CM_ "AUTOGENERATED FILE, DO NOT EDIT";

CM_ "Imported file _nissan_common.dbc starts here";
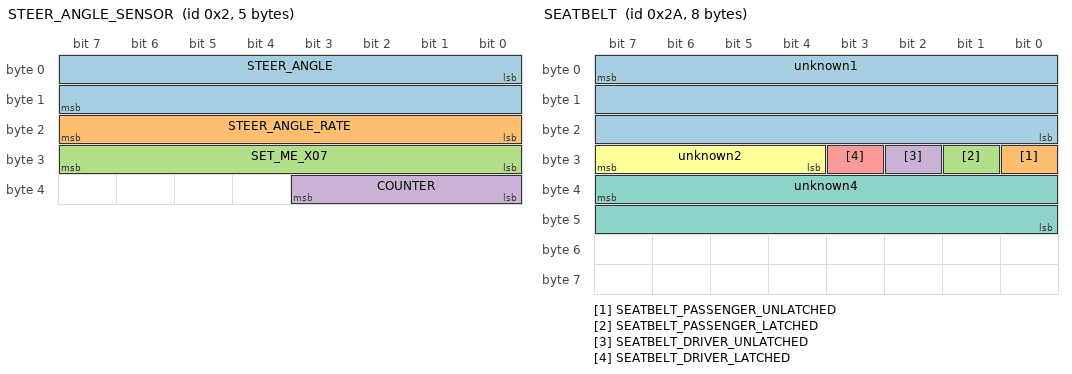
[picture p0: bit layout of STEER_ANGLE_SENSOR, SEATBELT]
BO_ 2 STEER_ANGLE_SENSOR: 5 XXX
 SG_ STEER_ANGLE : 0|16@1- (-0.1,0) [0|65535] "" XXX
 SG_ STEER_ANGLE_RATE : 16|8@1+ (1,0) [0|255] "" XXX
 SG_ SET_ME_X07 : 24|8@1+ (1,0) [0|255] "" XXX
 SG_ COUNTER : 32|4@1+ (1,0) [0|15] "" XXX

BO_ 42 SEATBELT: 8 XXX
 SG_ unknown1 : 7|24@0+ (1,0) [0|16777215] "" XXX
 SG_ SEATBELT_PASSENGER_UNLATCHED : 24|1@0+ (1,0) [0|1] "" XXX
 SG_ SEATBELT_PASSENGER_LATCHED : 25|1@0+ (1,0) [0|1] "" XXX
 SG_ SEATBELT_DRIVER_UNLATCHED : 26|1@0+ (1,0) [0|1] "" XXX
 SG_ SEATBELT_DRIVER_LATCHED : 27|1@1+ (1,0) [0|3] "" XXX
 SG_ unknown2 : 31|4@0+ (1,0) [0|15] "" XXX
 SG_ unknown4 : 39|16@0+ (1,0) [0|65535] "" XXX

BO_ 264 NEW_MSG_108: 3 XXX

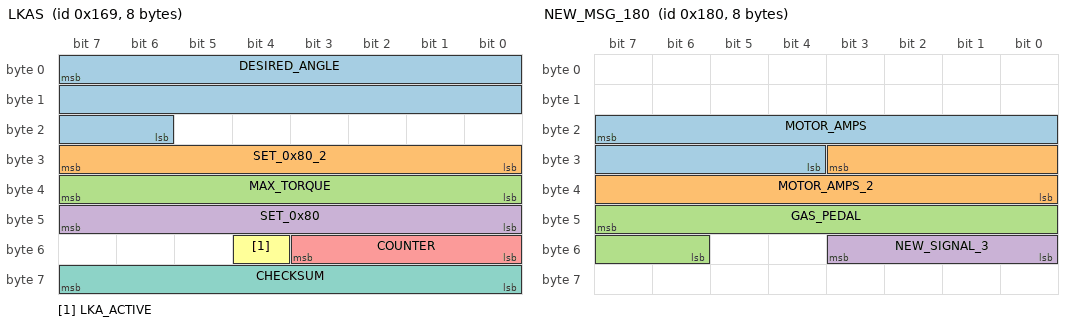
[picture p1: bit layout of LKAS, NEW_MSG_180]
BO_ 361 LKAS: 8 XXX
 SG_ DESIRED_ANGLE : 7|18@0+ (-0.01,1310) [-1311.43|1310] "" XXX
 SG_ SET_0x80_2 : 31|8@0+ (1,0) [0|255] "" XXX
 SG_ MAX_TORQUE : 39|8@0+ (0.01,0) [0|255] "Nm" XXX
 SG_ SET_0x80 : 47|8@0+ (1,0) [0|255] "" XXX
 SG_ COUNTER : 51|4@0+ (1,0) [0|15] "" XXX
 SG_ LKA_ACTIVE : 52|1@0+ (1,0) [0|15] "" XXX
 SG_ CHECKSUM : 63|8@0+ (1,0) [0|255] "" XXX

BO_ 372 NEW_MSG_174: 8 XXX
 SG_ GEARBOX_STATUS : 24|8@1+ (1,0) [0|255] "" XXX
 SG_ COUNTER : 32|4@1+ (1,0) [0|15] "" XXX

BO_ 384 NEW_MSG_180: 8 XXX
 SG_ MOTOR_AMPS : 23|12@0- (1,0) [0|4095] "" XXX
 SG_ MOTOR_AMPS_2 : 27|12@0- (1,0) [0|4095] "" XXX
 SG_ GAS_PEDAL : 47|10@0+ (1,0) [0|1023] "" XXX
 SG_ NEW_SIGNAL_3 : 51|4@0+ (1,0) [0|15] "" XXX

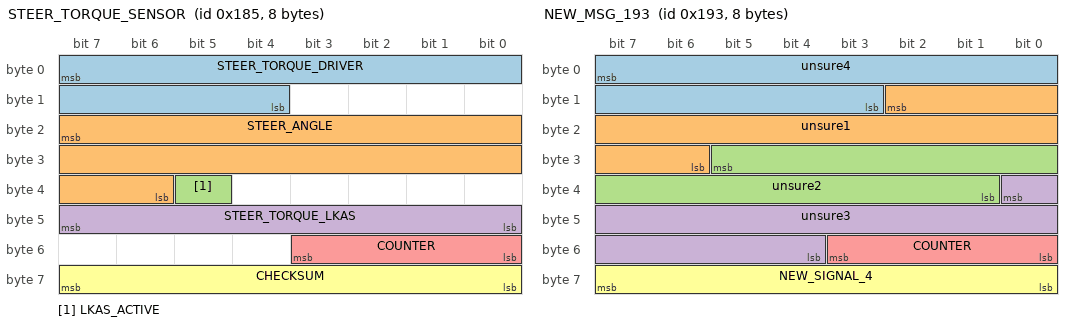
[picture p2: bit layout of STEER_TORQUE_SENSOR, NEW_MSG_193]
BO_ 389 STEER_TORQUE_SENSOR: 8 XXX
 SG_ STEER_TORQUE_DRIVER : 7|12@0+ (-0.01,20.47) [0|4095] "Nm" XXX
 SG_ STEER_ANGLE : 23|18@0+ (-0.01,1310) [0|262143] "" XXX
 SG_ LKAS_ACTIVE : 37|1@0+ (1,0) [0|3] "" XXX
 SG_ STEER_TORQUE_LKAS : 47|8@0+ (1,0) [0|255] "" XXX
 SG_ COUNTER : 51|4@0+ (1,0) [0|15] "" XXX
 SG_ CHECKSUM : 63|8@0+ (1,0) [0|127] "" XXX

BO_ 403 NEW_MSG_193: 8 XXX
 SG_ unsure4 : 7|13@0+ (0.1,-400) [0|8191] "" XXX
 SG_ unsure1 : 10|13@0+ (0.1,-400) [0|8191] "" XXX
 SG_ unsure2 : 29|13@0+ (0.1,-400) [0|8191] "" XXX
 SG_ unsure3 : 32|13@0+ (0.1,-400) [0|8191] "" XXX
 SG_ COUNTER : 51|4@0+ (1,0) [0|15] "" XXX
 SG_ NEW_SIGNAL_4 : 63|8@0+ (1,0) [0|255] "" XXX

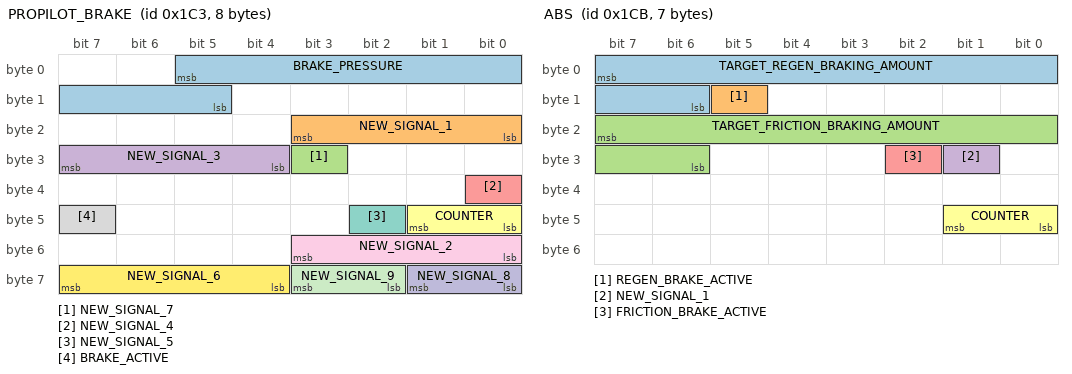
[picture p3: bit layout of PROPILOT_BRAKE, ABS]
BO_ 451 PROPILOT_BRAKE: 8 XXX
 SG_ BRAKE_PRESSURE : 5|9@0+ (1,0) [0|511] "" XXX
 SG_ NEW_SIGNAL_1 : 19|4@0+ (1,0) [0|4095] "" XXX
 SG_ NEW_SIGNAL_7 : 27|1@0+ (1,0) [0|1] "" XXX
 SG_ NEW_SIGNAL_3 : 31|4@0+ (1,0) [0|31] "" XXX
 SG_ NEW_SIGNAL_4 : 32|1@0+ (1,0) [0|1] "" XXX
 SG_ COUNTER : 40|2@1+ (1,0) [0|3] "" XXX
 SG_ NEW_SIGNAL_5 : 42|1@0+ (1,0) [0|1] "" XXX
 SG_ BRAKE_ACTIVE : 47|1@0+ (1,0) [0|1] "" XXX
 SG_ NEW_SIGNAL_2 : 48|4@1+ (1,0) [0|255] "" XXX
 SG_ NEW_SIGNAL_8 : 56|2@1+ (1,0) [0|3] "" XXX
 SG_ NEW_SIGNAL_9 : 58|2@1+ (1,0) [0|3] "" XXX
 SG_ NEW_SIGNAL_6 : 63|4@0+ (1,0) [0|15] "" XXX

BO_ 459 ABS: 7 ABS
 SG_ TARGET_REGEN_BRAKING_AMOUNT : 7|10@0+ (1,0) [0|1023] "" XXX
 SG_ REGEN_BRAKE_ACTIVE : 13|1@0+ (1,0) [0|1] "" XXX
 SG_ TARGET_FRICTION_BRAKING_AMOUNT : 23|10@0+ (1,0) [0|1023] "" XXX
 SG_ NEW_SIGNAL_1 : 25|1@0+ (1,0) [0|1] "" XXX
 SG_ FRICTION_BRAKE_ACTIVE : 26|1@0+ (1,0) [0|1] "" XXX
 SG_ COUNTER : 41|2@0+ (1,0) [0|3] "" XXX

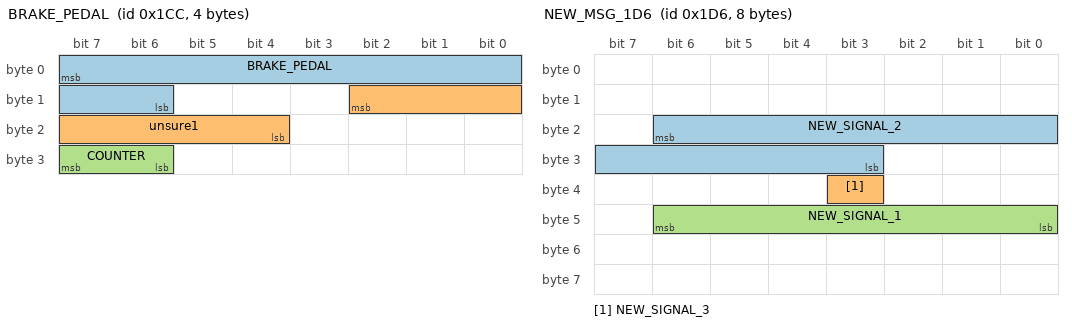
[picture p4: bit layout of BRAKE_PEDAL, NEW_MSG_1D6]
BO_ 460 BRAKE_PEDAL: 4 ABS
 SG_ BRAKE_PEDAL : 7|10@0+ (1,0) [0|256] "" XXX
 SG_ unsure1 : 10|7@0+ (1,0) [0|1023] "" XXX
 SG_ COUNTER : 30|2@1+ (1,0) [0|3] "" XXX

BO_ 470 NEW_MSG_1D6: 8 XXX
 SG_ NEW_SIGNAL_2 : 22|12@0+ (1,0) [0|2047] "" XXX
 SG_ NEW_SIGNAL_3 : 35|1@0+ (1,0) [0|1] "" XXX
 SG_ NEW_SIGNAL_1 : 40|7@1+ (1,0) [0|127] "" XXX

BO_ 520 NEW_MSG_208: 1 XXX
 SG_ NEW_SIGNAL_1 : 7|1@0+ (1,0) [0|1] "" XXX

BO_ 569 CRUISE_THROTTLE: 8 XXX
 SG_ GAS_PEDAL : 7|8@0+ (1,0) [0|255] "" XXX
 SG_ GAS_PEDAL_INVERTED : 15|8@0+ (1,0) [0|255] "" XXX
 SG_ unsure2 : 16|1@0+ (1,0) [0|1] "" XXX
 SG_ CRUISE_AVAILABLE : 17|1@0+ (1,0) [0|1] "" XXX
 SG_ unsure1 : 23|6@0+ (1,0) [0|63] "" XXX
 SG_ PROPILOT_BUTTON : 24|1@0+ (1,0) [0|1] "" XXX
 SG_ CANCEL_BUTTON : 25|1@0+ (1,0) [0|1] "" XXX
 SG_ FOLLOW_DISTANCE_BUTTON : 26|1@0+ (1,0) [0|1] "" XXX
 SG_ SET_BUTTON : 27|1@0+ (1,0) [0|1] "" XXX
 SG_ RES_BUTTON : 28|1@0+ (1,0) [0|1] "" XXX
 SG_ NO_BUTTON_PRESSED : 29|1@0+ (1,0) [0|1] "" XXX
 SG_ unsure3 : 31|2@0+ (1,0) [0|3] "" XXX
 SG_ COUNTER : 32|2@1+ (1,0) [0|3] "" XXX
 SG_ DRIVER_BRAKE_PRESSED : 37|1@0+ (1,0) [0|1] "" XXX
 SG_ DRIVER_BRAKE_NOT_PRESSED : 38|1@0+ (1,0) [0|1] "" XXX
 SG_ unsure5 : 47|8@0+ (1,0) [0|255] "" XXX
 SG_ unsure6 : 55|8@0+ (1,0) [0|255] "" XXX
 SG_ unsure7 : 63|8@0+ (1,0) [0|255] "" XXX

BO_ 581 NEW_MSG_245: 8 XXX

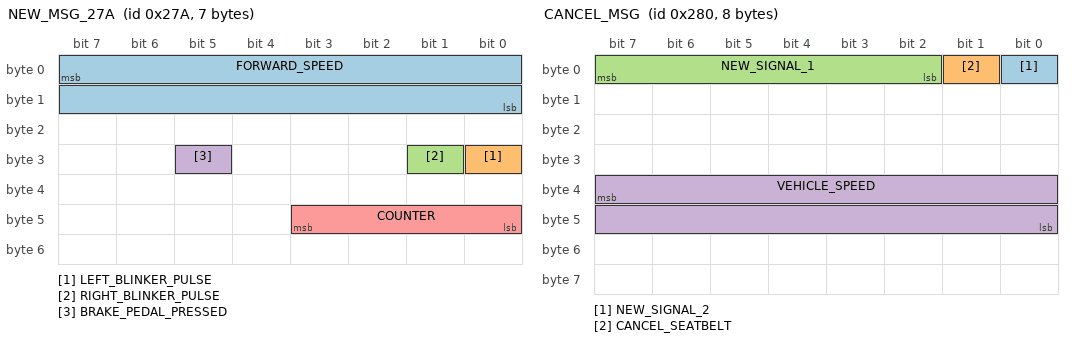
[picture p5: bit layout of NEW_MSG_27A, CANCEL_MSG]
BO_ 634 NEW_MSG_27A: 7 XXX
 SG_ FORWARD_SPEED : 7|16@0+ (0.1,0) [0|65535] "KPH" XXX
 SG_ LEFT_BLINKER_PULSE : 24|1@0+ (1,0) [0|1] "" XXX
 SG_ RIGHT_BLINKER_PULSE : 25|1@0+ (1,0) [0|1] "" XXX
 SG_ BRAKE_PEDAL_PRESSED : 29|1@0+ (1,0) [0|1] "" XXX
 SG_ COUNTER : 40|4@1+ (1,0) [0|15] "" XXX

BO_ 640 CANCEL_MSG: 8 XXX
 SG_ NEW_SIGNAL_2 : 0|1@0+ (1,0) [0|1] "" XXX
 SG_ CANCEL_SEATBELT : 1|1@0+ (1,0) [0|1] "" XXX
 SG_ NEW_SIGNAL_1 : 7|6@0+ (1,0) [0|63] "" XXX
 SG_ VEHICLE_SPEED : 39|16@0+ (0.0062,0) [0|65535] "" XXX

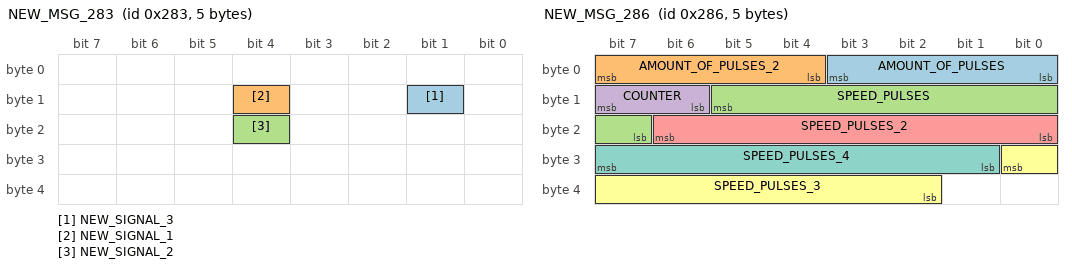
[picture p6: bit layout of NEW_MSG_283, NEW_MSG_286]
BO_ 643 NEW_MSG_283: 5 XXX
 SG_ NEW_SIGNAL_3 : 9|1@0+ (1,0) [0|1] "" XXX
 SG_ NEW_SIGNAL_1 : 12|1@0+ (1,0) [0|1] "" XXX
 SG_ NEW_SIGNAL_2 : 20|1@0+ (1,0) [0|1] "" XXX

BO_ 644 WHEEL_SPEEDS_FRONT: 8 XXX
 SG_ WHEEL_SPEED_FR : 7|16@0+ (0.005,0) [0|65535] "KPH" XXX
 SG_ WHEEL_SPEED_FL : 23|16@0+ (0.005,0) [0|65535] "KPH" XXX

BO_ 645 WHEEL_SPEEDS_REAR: 8 XXX
 SG_ WHEEL_SPEED_RR : 7|16@0+ (0.005,0) [0|65535] "KPH" XXX
 SG_ WHEEL_SPEED_RL : 23|16@0+ (0.005,0) [0|65535] "KPH" XXX

BO_ 646 NEW_MSG_286: 5 XXX
 SG_ AMOUNT_OF_PULSES : 0|4@1+ (1,0) [0|15] "" XXX
 SG_ AMOUNT_OF_PULSES_2 : 4|4@1+ (1,0) [0|15] "" XXX
 SG_ SPEED_PULSES : 13|7@0+ (1,0) [0|31] "" XXX
 SG_ COUNTER : 14|2@1+ (1,0) [0|3] "" XXX
 SG_ SPEED_PULSES_2 : 22|7@0+ (1,0) [0|63] "" XXX
 SG_ SPEED_PULSES_3 : 24|7@0+ (1,0) [0|63] "" XXX
 SG_ SPEED_PULSES_4 : 31|7@0+ (1,0) [0|63] "" XXX

BO_ 648 NEW_MSG_288: 5 XXX
 SG_ NOT_IN_PARK : 11|1@0+ (1,0) [0|1] "" XXX

BO_ 654 NEW_MSG_28E: 6 XXX
 SG_ PROPILOT_BRAKE_ACTIVE : 16|1@0+ (1,0) [0|1] "" XXX
 SG_ COUNTER : 41|2@1+ (1,0) [0|3] "" XXX

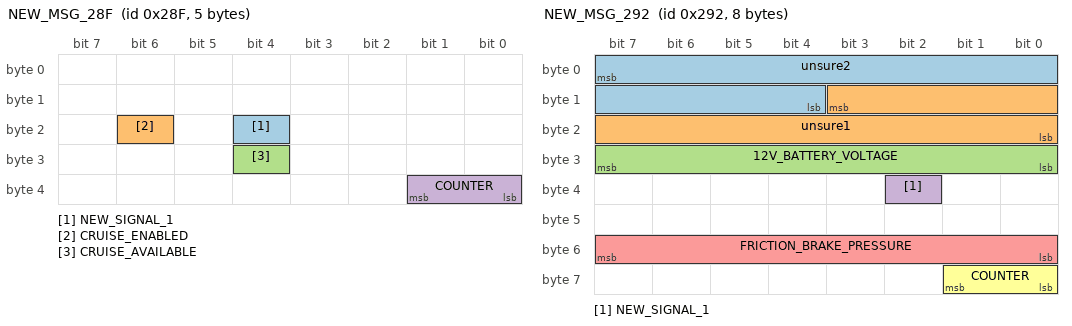
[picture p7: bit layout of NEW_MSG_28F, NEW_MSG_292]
BO_ 655 NEW_MSG_28F: 5 XXX
 SG_ NEW_SIGNAL_1 : 20|1@0+ (1,0) [0|1] "" XXX
 SG_ CRUISE_ENABLED : 22|1@0+ (1,0) [0|1] "" XXX
 SG_ CRUISE_AVAILABLE : 28|1@0+ (1,0) [0|1] "" XXX
 SG_ COUNTER : 32|2@1+ (1,0) [0|3] "" XXX

BO_ 658 NEW_MSG_292: 8 XXX
 SG_ unsure2 : 7|12@0+ (1,0) [0|4095] "" XXX
 SG_ unsure1 : 11|12@0+ (1,0) [0|4095] "" XXX
 SG_ 12V_BATTERY_VOLTAGE : 31|8@0+ (0.1,0) [0|255] "V" XXX
 SG_ NEW_SIGNAL_1 : 34|1@0+ (1,0) [0|1] "" XXX
 SG_ FRICTION_BRAKE_PRESSURE : 48|8@1+ (1,0) [0|255] "" XXX
 SG_ COUNTER : 56|2@1+ (1,0) [0|3] "" XXX

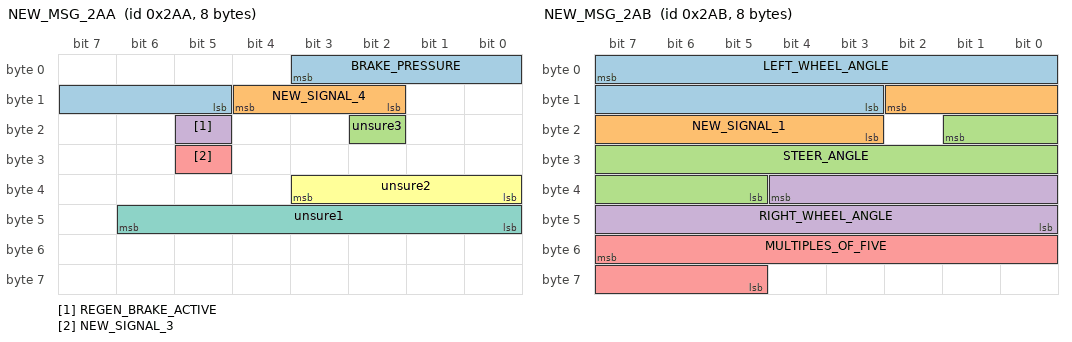
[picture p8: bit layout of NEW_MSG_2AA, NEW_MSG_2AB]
BO_ 682 NEW_MSG_2AA: 8 XXX
 SG_ BRAKE_PRESSURE : 3|7@0+ (1,0) [0|3] "" XXX
 SG_ NEW_SIGNAL_4 : 12|3@0+ (1,0) [0|7] "" XXX
 SG_ unsure3 : 18|1@0+ (1,0) [0|1] "" XXX
 SG_ REGEN_BRAKE_ACTIVE : 21|1@0+ (1,0) [0|1] "" XXX
 SG_ NEW_SIGNAL_3 : 29|1@0+ (1,0) [0|1] "" XXX
 SG_ unsure2 : 35|4@0+ (1,0) [0|15] "" XXX
 SG_ unsure1 : 46|7@0+ (1,0) [0|127] "" XXX

BO_ 683 NEW_MSG_2AB: 8 XXX
 SG_ LEFT_WHEEL_ANGLE : 7|13@0- (0.1,0) [0|4095] "" XXX
 SG_ NEW_SIGNAL_1 : 10|8@0- (1,0) [0|255] "" XXX
 SG_ STEER_ANGLE : 17|13@0- (0.1,0) [0|511] "" XXX
 SG_ RIGHT_WHEEL_ANGLE : 36|13@0- (0.1,0) [0|255] "" XXX
 SG_ MULTIPLES_OF_FIVE : 55|11@0+ (1,-1024) [0|255] "" XXX

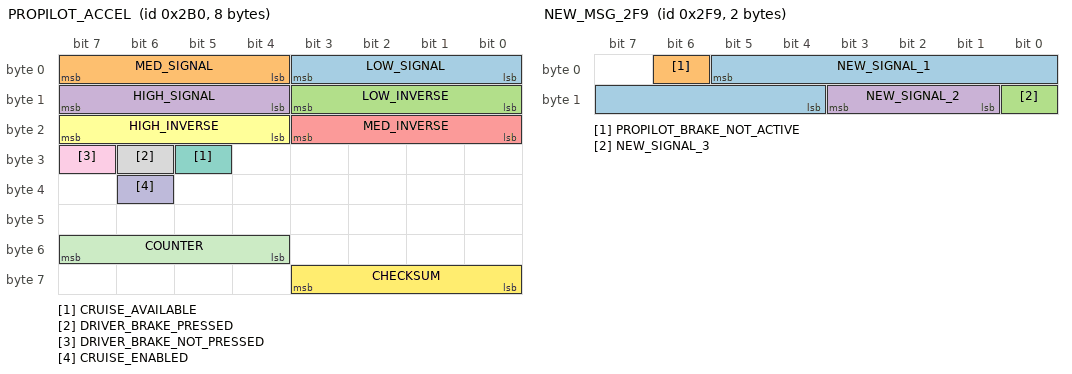
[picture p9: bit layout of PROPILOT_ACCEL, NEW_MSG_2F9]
BO_ 688 PROPILOT_ACCEL: 8 XXX
 SG_ LOW_SIGNAL : 0|4@1+ (1,0) [0|15] "" XXX
 SG_ MED_SIGNAL : 4|4@1+ (16,0) [0|15] "" XXX
 SG_ LOW_INVERSE : 11|4@0+ (1,0) [0|15] "" XXX
 SG_ HIGH_SIGNAL : 15|4@0+ (4,0) [0|15] "" XXX
 SG_ MED_INVERSE : 19|4@0+ (16,0) [0|15] "" XXX
 SG_ HIGH_INVERSE : 23|4@0+ (256,0) [0|15] "" XXX
 SG_ CRUISE_AVAILABLE : 29|1@0+ (1,0) [0|1] "" XXX
 SG_ DRIVER_BRAKE_PRESSED : 30|1@0+ (1,0) [0|1] "" XXX
 SG_ DRIVER_BRAKE_NOT_PRESSED : 31|1@0+ (1,0) [0|1] "" XXX
 SG_ CRUISE_ENABLED : 38|1@0+ (1,0) [0|1] "" XXX
 SG_ COUNTER : 52|4@1+ (1,0) [0|15] "" XXX
 SG_ CHECKSUM : 59|4@0+ (1,0) [0|15] "" XXX

BO_ 689 PROPILOT_HUD: 8 XXX
 SG_ unknown02 : 1|2@0+ (1,0) [0|3] "" XXX
 SG_ FOLLOW_DISTANCE : 3|2@0+ (1,0) [0|3] "" XXX
 SG_ unknown05 : 5|2@0+ (1,0) [0|3] "" XXX
 SG_ SPEED_SET_ICON : 7|2@0+ (1,0) [0|3] "" XXX
 SG_ unknown08 : 8|7@0+ (1,0) [0|63] "" XXX
 SG_ LARGE_WARNING_FLASHING : 9|1@0+ (1,0) [0|1] "" XXX
 SG_ RIGHT_BSW_FLASH : 10|1@0+ (1,0) [0|1] "" XXX
 SG_ LEFT_BSW_FLASH : 11|1@0+ (1,0) [0|1] "" XXX
 SG_ RIGHT_LANE_YELLOW_FLASH : 12|1@0+ (1,0) [0|1] "" XXX
 SG_ LEFT_LANE_YELLOW_FLASH : 13|1@0+ (1,0) [0|1] "" XXX
 SG_ LEAD_CAR : 14|1@0+ (1,0) [0|1] "" XXX
 SG_ LEAD_CAR_ERROR : 15|1@0+ (1,0) [0|1] "" XXX
 SG_ FRONT_RADAR_ERROR : 16|1@0+ (1,0) [0|1] "" XXX
 SG_ FRONT_RADAR_ERROR_FLASHING : 17|1@0+ (1,0) [0|1] "" XXX
 SG_ RIGHT_LANE_GREEN : 24|1@0+ (1,0) [0|1] "" XXX
 SG_ LEFT_LANE_GREEN : 25|1@0+ (1,0) [0|1] "" XXX
 SG_ unknown26 : 26|1@0+ (1,0) [0|1] "" XXX
 SG_ SIDE_RADAR_ERROR_FLASHING3 : 27|1@0+ (1,0) [0|1] "" XXX
 SG_ unknown28 : 28|1@0+ (1,0) [0|1] "" XXX
 SG_ LKAS_ERROR_FLASHING : 29|1@0+ (1,0) [0|1] "" XXX
 SG_ unknown31 : 31|2@0+ (1,0) [0|3] "" XXX
 SG_ SET_SPEED : 39|8@0+ (1,0) [0|255] "" XXX
 SG_ SMALL_STEERING_WHEEL_ICON : 42|3@0+ (1,0) [0|7] "" XXX
 SG_ unknown43 : 43|1@0+ (1,0) [0|1] "" XXX
 SG_ SAFETY_SHIELD_ACTIVE : 44|1@0+ (1,0) [0|1] "" XXX
 SG_ AUDIBLE_TONE : 47|3@0+ (1,0) [0|8] "" XXX
 SG_ unknown55 : 55|8@0+ (1,0) [0|63] "" XXX
 SG_ unknown59 : 59|4@0+ (1,0) [0|15] "" XXX
 SG_ LARGE_STEERING_WHEEL_ICON : 61|2@0+ (1,0) [0|3] "" XXX
 SG_ RIGHT_LANE_GREEN_FLASH : 62|1@0+ (1,0) [0|1] "" XXX
 SG_ LEFT_LANE_GREEN_FLASH : 63|1@0+ (1,0) [0|1] "" XXX

BO_ 724 NEW_MSG_2D4: 6 XXX
 SG_ COUNTER : 33|2@0+ (1,0) [0|3] "" XXX
 SG_ CRUISE_ENABLED : 39|1@0+ (1,0) [0|1] "" XXX

BO_ 758 NEW_MSG_2F6: 3 XXX

BO_ 761 NEW_MSG_2F9: 2 XXX
 SG_ NEW_SIGNAL_1 : 5|10@0+ (1,0) [0|1023] "" XXX
 SG_ PROPILOT_BRAKE_NOT_ACTIVE : 6|1@0+ (1,0) [0|1] "" XXX
 SG_ NEW_SIGNAL_3 : 8|1@0+ (1,0) [0|1] "" XXX
 SG_ NEW_SIGNAL_2 : 9|3@1+ (1,0) [0|7] "" XXX

BO_ 783 CRUISE_STATE: 3 XXX
 SG_ CRUISE_ENABLED : 3|1@0+ (1,0) [0|1] "" XXX
 SG_ COUNTER : 8|4@1+ (1,0) [0|15] "" XXX

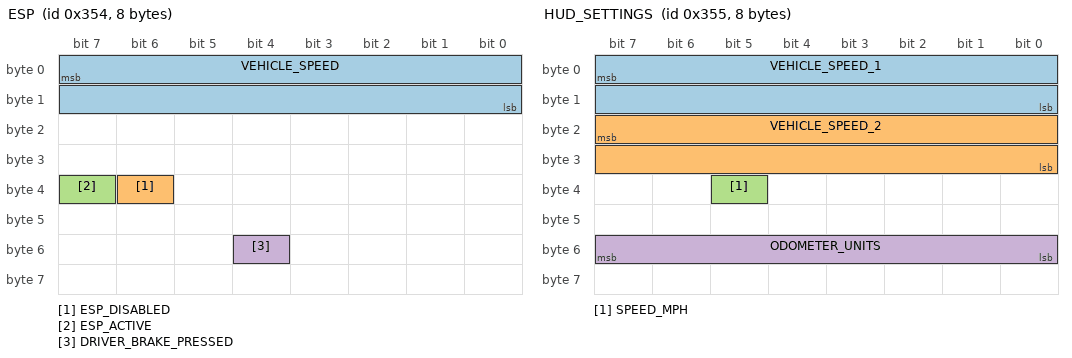
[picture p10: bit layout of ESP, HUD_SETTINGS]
BO_ 852 ESP: 8 XXX
 SG_ VEHICLE_SPEED : 7|16@0+ (0.01,0) [0|65535] "" XXX
 SG_ ESP_DISABLED : 38|1@0+ (1,0) [0|1] "" XXX
 SG_ ESP_ACTIVE : 39|1@0+ (1,0) [0|1] "" XXX
 SG_ DRIVER_BRAKE_PRESSED : 52|1@0+ (1,0) [0|1] "" XXX

BO_ 853 HUD_SETTINGS: 8 XXX
 SG_ VEHICLE_SPEED_1 : 7|16@0+ (0.01,0) [0|65535] "" XXX
 SG_ VEHICLE_SPEED_2 : 23|16@0+ (0.01,0) [0|65535] "" XXX
 SG_ SPEED_MPH : 37|1@0+ (1,0) [0|1] "" XXX
 SG_ ODOMETER_UNITS : 55|8@0+ (1,0) [0|255] "" XXX

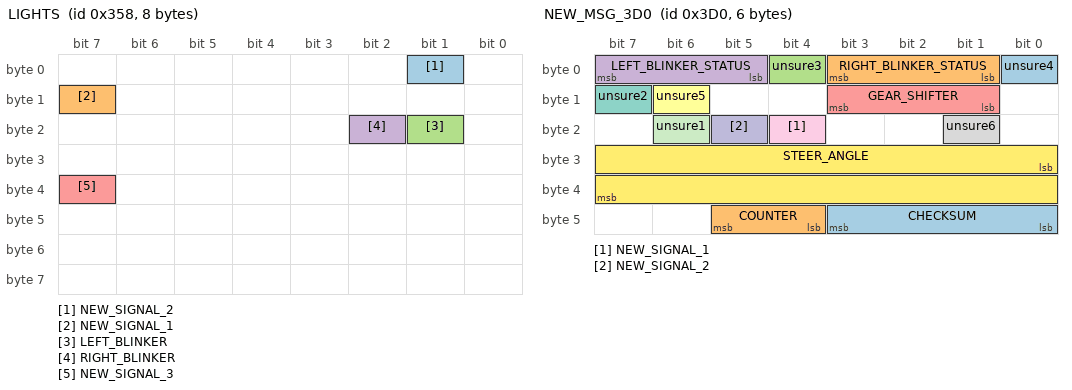
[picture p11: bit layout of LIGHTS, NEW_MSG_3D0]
BO_ 856 LIGHTS: 8 BCM
 SG_ NEW_SIGNAL_2 : 1|1@0+ (1,0) [0|1] "" XXX
 SG_ NEW_SIGNAL_1 : 15|1@0+ (1,0) [0|1] "" XXX
 SG_ LEFT_BLINKER : 17|1@0+ (1,0) [0|1] "" XXX
 SG_ RIGHT_BLINKER : 18|1@0+ (1,0) [0|1] "" XXX
 SG_ NEW_SIGNAL_3 : 39|1@0+ (1,0) [0|1] "" XXX

BO_ 861 NEW_MSG_35D: 8 XXX
 SG_ NEW_SIGNAL_1 : 7|2@0+ (1,0) [0|3] "" XXX
 SG_ DRIVER_BRAKE_PRESSED : 36|1@0+ (1,0) [0|1] "" XXX

BO_ 976 NEW_MSG_3D0: 6 XXX
 SG_ unsure4 : 0|1@0+ (1,0) [0|1] "" XXX
 SG_ RIGHT_BLINKER_STATUS : 3|3@0+ (1,0) [0|7] "" XXX
 SG_ unsure3 : 4|1@0+ (1,0) [0|1] "" XXX
 SG_ LEFT_BLINKER_STATUS : 5|3@1+ (1,0) [0|7] "" XXX
 SG_ GEAR_SHIFTER : 9|3@1+ (1,0) [0|7] "" XXX
 SG_ unsure5 : 14|1@0+ (1,0) [0|1] "" XXX
 SG_ unsure2 : 15|1@0+ (1,0) [0|1] "" XXX
 SG_ unsure6 : 17|1@0+ (1,0) [0|1] "" XXX
 SG_ NEW_SIGNAL_1 : 20|1@0+ (1,0) [0|1] "" XXX
 SG_ NEW_SIGNAL_2 : 21|1@0+ (1,0) [0|1] "" XXX
 SG_ unsure1 : 22|1@0+ (1,0) [0|1] "" XXX
 SG_ STEER_ANGLE : 24|16@1- (-0.1,0) [0|65535] "deg" XXX
 SG_ CHECKSUM : 43|4@0+ (1,0) [0|15] "" XXX
 SG_ COUNTER : 44|2@1+ (1,0) [0|3] "" XXX

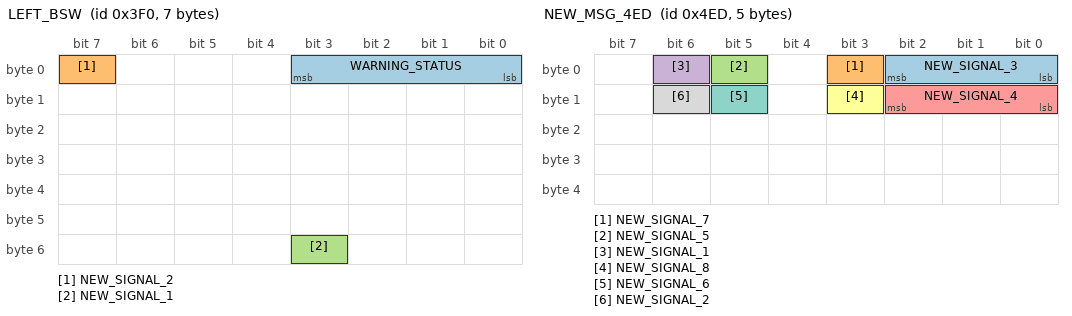
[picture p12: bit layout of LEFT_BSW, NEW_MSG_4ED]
BO_ 1008 LEFT_BSW: 7 XXX
 SG_ WARNING_STATUS : 3|4@0+ (1,0) [0|15] "" XXX
 SG_ NEW_SIGNAL_2 : 7|1@0+ (1,0) [0|1] "" XXX
 SG_ NEW_SIGNAL_1 : 51|1@0+ (1,0) [0|1] "" XXX

BO_ 1011 RIGHT_BSW: 7 BSW
 SG_ WARNING_STATUS : 3|4@0+ (1,0) [0|15] "" XXX
 SG_ NEW_SIGNAL_1 : 7|1@0+ (1,0) [0|1] "" XXX

BO_ 1057 GEARBOX: 3 VCM
 SG_ GEAR_SHIFTER : 5|3@0+ (1,0) [0|255] "" XXX

BO_ 1227 LKAS_SETTINGS: 8 XXX
 SG_ LKAS_ENABLED : 51|1@0+ (1,0) [0|1] "" XXX

BO_ 1228 PROPILOT_HUD_INFO_MSG: 8 XXX
 SG_ NA_HIGH_ACCEL_TEMP : 0|1@0+ (1,0) [0|1] "" XXX
 SG_ unknown07 : 7|7@0+ (1,0) [0|127] "" XXX
 SG_ SIDE_RADAR_NA_HIGH_CABIN_TEMP : 8|1@0+ (1,0) [0|1] "" XXX
 SG_ unknown10 : 10|2@0+ (1,0) [0|3] "" XXX
 SG_ SIDE_RADAR_MALFUNCTION : 11|1@0+ (1,0) [0|1] "" XXX
 SG_ LKAS_MALFUNCTION : 12|1@0+ (1,0) [0|1] "" XXX
 SG_ FRONT_RADAR_MALFUNCTION : 13|1@0+ (1,0) [0|1] "" XXX
 SG_ SIDE_RADAR_NA_CLEAN_REAR_CAMERA : 14|1@0+ (1,0) [0|1] "" XXX
 SG_ unknown15 : 15|1@0+ (1,0) [0|1] "" XXX
 SG_ NA_POOR_ROAD_CONDITIONS : 16|1@0+ (1,0) [0|1] "" XXX
 SG_ CURRENTLY_UNAVAILABLE : 17|1@0+ (1,0) [0|1] "" XXX
 SG_ SAFETY_SHIELD_OFF : 18|1@0+ (1,0) [0|1] "" XXX
 SG_ unknown19 : 19|1@0+ (1,0) [0|1] "" XXX
 SG_ FRONT_COLLISION_NA_FRONT_RADAR_OBSTRUCTION : 20|1@0+ (1,0) [0|1] "" XXX
 SG_ unknown23 : 23|3@0+ (1,0) [0|7] "" XXX
 SG_ PEDAL_MISSAPPLICATION_SYSTEM_ACTIVATED : 24|1@0+ (1,0) [0|1] "" XXX
 SG_ SIDE_IMPACT_NA_RADAR_OBSTRUCTION : 25|1@0+ (1,0) [0|1] "" XXX
 SG_ unknown31 : 31|6@0+ (1,0) [0|63] "" XXX
 SG_ unknown32 : 32|1@0+ (1,0) [0|1] "" XXX
 SG_ WARNING_DO_NOT_ENTER : 33|1@0+ (1,0) [0|1] "" XXX
 SG_ SIDE_IMPACT_SYSTEM_OFF : 34|1@0+ (1,0) [0|1] "" XXX
 SG_ SIDE_IMPACT_MALFUNCTION : 35|1@0+ (1,0) [0|1] "" XXX
 SG_ FRONT_COLLISION_MALFUNCTION : 36|1@0+ (1,0) [0|1] "" XXX
 SG_ SIDE_RADAR_MALFUNCTION2 : 37|1@0+ (1,0) [0|1] "" XXX
 SG_ LKAS_MALFUNCTION2 : 38|1@0+ (1,0) [0|1] "" XXX
 SG_ FRONT_RADAR_MALFUNCTION2 : 39|1@0+ (1,0) [0|1] "" XXX
 SG_ PROPILOT_NA_MSGS : 42|3@0+ (1,0) [0|7] "" XXX
 SG_ BOTTOM_MSG : 45|3@0+ (1,0) [0|7] "" XXX
 SG_ unknown46 : 46|1@0+ (1,0) [0|1] "" XXX
 SG_ HANDS_ON_WHEEL_WARNING : 47|1@0+ (1,0) [0|1] "" XXX
 SG_ unknown50 : 50|3@0+ (1,0) [0|7] "" XXX
 SG_ WARNING_STEP_ON_BRAKE_NOW : 51|1@0+ (1,0) [0|1] "" XXX
 SG_ PROPILOT_NA_FRONT_CAMERA_OBSTRUCTED : 52|1@0+ (1,0) [0|1] "" XXX
 SG_ PROPILOT_NA_HIGH_CABIN_TEMP : 53|1@0+ (1,0) [0|1] "" XXX
 SG_ WARNING_PROPILOT_MALFUNCTION : 54|1@0+ (1,0) [0|3] "" XXX
 SG_ unknown55 : 55|1@0+ (1,0) [0|1] "" XXX
 SG_ unknown61 : 61|6@0+ (1,0) [0|63] "" XXX
 SG_ ACC_UNAVAILABLE_HIGH_CABIN_TEMP : 62|1@0+ (1,0) [0|1] "" XXX
 SG_ ACC_NA_FRONT_CAMERA_IMPARED : 63|1@0+ (1,0) [0|1] "" XXX

BO_ 1261 NEW_MSG_4ED: 5 XXX
 SG_ NEW_SIGNAL_3 : 2|3@0+ (1,0) [0|7] "" XXX
 SG_ NEW_SIGNAL_7 : 3|1@0+ (1,0) [0|1] "" XXX
 SG_ NEW_SIGNAL_5 : 5|1@0+ (1,0) [0|1] "" XXX
 SG_ NEW_SIGNAL_1 : 6|1@0+ (1,0) [0|1] "" XXX
 SG_ NEW_SIGNAL_4 : 10|3@0+ (1,0) [0|7] "" XXX
 SG_ NEW_SIGNAL_8 : 11|1@0+ (1,0) [0|1] "" XXX
 SG_ NEW_SIGNAL_6 : 13|1@0+ (1,0) [0|1] "" XXX
 SG_ NEW_SIGNAL_2 : 14|1@0+ (1,0) [0|1] "" XXX

BO_ 1342 NEW_MSG_53E: 1 XXX
 SG_ NEW_SIGNAL_1 : 4|2@1+ (1,0) [0|3] "" XXX

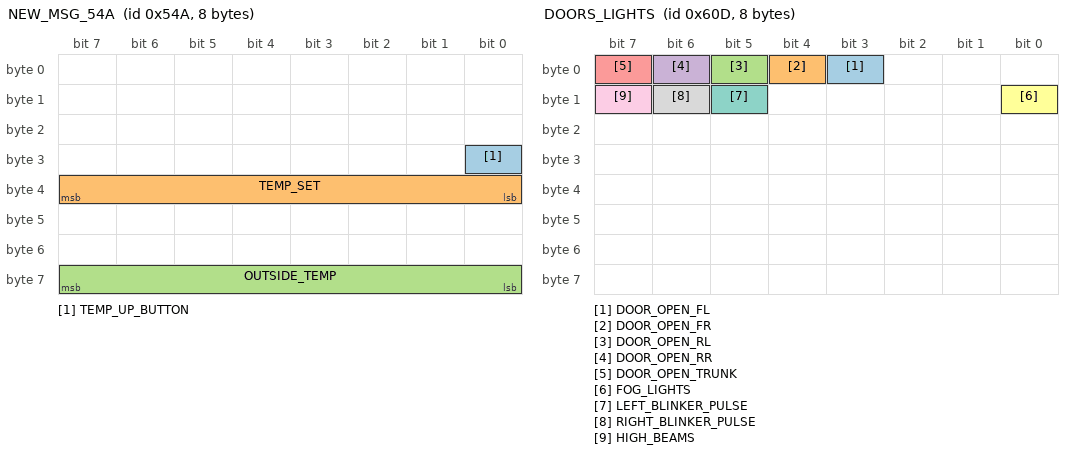
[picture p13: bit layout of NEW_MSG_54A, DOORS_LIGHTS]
BO_ 1354 NEW_MSG_54A: 8 HVAC
 SG_ TEMP_UP_BUTTON : 24|1@0+ (1,0) [0|1] "" XXX
 SG_ TEMP_SET : 39|8@0+ (1,0) [0|255] "" XXX
 SG_ OUTSIDE_TEMP : 56|8@1+ (1,-41) [0|255] "F" XXX

BO_ 1361 NEW_MSG_551: 8 XXX
 SG_ NEW_SIGNAL_1 : 31|1@0+ (1,0) [0|1] "" XXX

BO_ 1459 HV_BATTERY_CHARGE_CAPACITY: 8 XXX
 SG_ GIDS : 24|9@0+ (1,0) [0|511] "" XXX

BO_ 1477 ODOMETER: 8 XXX
 SG_ NEW_SIGNAL_1 : 2|1@0+ (1,0) [0|1] "" XXX
 SG_ ODOMETER : 15|24@0+ (1,0) [0|16777215] "" XXX

BO_ 1497 NEW_MSG_5D9: 3 XXX
 SG_ NEW_SIGNAL_1 : 4|1@0+ (1,0) [0|1] "" XXX
 SG_ NEW_SIGNAL_2 : 22|2@1+ (1,0) [0|3] "" XXX

BO_ 1549 DOORS_LIGHTS: 8 BCM
 SG_ DOOR_OPEN_FL : 3|1@0+ (1,0) [0|1] "" XXX
 SG_ DOOR_OPEN_FR : 4|1@0+ (1,0) [0|1] "" XXX
 SG_ DOOR_OPEN_RL : 5|1@0+ (1,0) [0|1] "" XXX
 SG_ DOOR_OPEN_RR : 6|1@0+ (1,0) [0|1] "" XXX
 SG_ DOOR_OPEN_TRUNK : 7|1@0+ (1,0) [0|1] "" XXX
 SG_ FOG_LIGHTS : 8|1@0+ (1,0) [0|1] "" XXX
 SG_ LEFT_BLINKER_PULSE : 13|1@0+ (1,0) [0|1] "" XXX
 SG_ RIGHT_BLINKER_PULSE : 14|1@0+ (1,0) [0|1] "" XXX
 SG_ HIGH_BEAMS : 15|1@0+ (1,0) [0|1] "" XXX

BO_ 1573 NEW_MSG_625: 6 XXX
 SG_ NEW_SIGNAL_1 : 1|2@1+ (1,0) [0|3] "" XXX
 SG_ HEADLIGHT_STATUS : 15|8@0+ (1,0) [0|255] "" XXX

BO_ 1821 NEW_MSG_71D: 8 XXX

BO_ 1837 NEW_MSG_72D: 8 XXX

BO_ 1856 ABS_QUERY: 8 XXX

BO_ 1859 BCM_QUERY: 8 XXX

BO_ 1860 HVAC_QUERY: 8 XXX

BO_ 1888 ABS_RESPONSE: 8 XXX

BO_ 1891 BCM_RESPONSE: 8 XXX

BO_ 1892 HVAC_RESPONSE: 8 XXX

BO_ 1943 VCM_QUERY: 8 XXX

BO_ 1946 VCM_RESPONSE: 8 XXX

VAL_ 372 GEARBOX_STATUS 187 "Drive" 170 "Park/Neutral" 153 "Reverse";
VAL_ 689 FOLLOW_DISTANCE 0 "NO_FOLLOW_DISTANCE" 1 "FOLLOW_DISTANCE_1" 2 "FOLLOW_DISTANCE_2" 3 "FOLLOW_DISTANCE_3";
VAL_ 689 SMALL_STEERING_WHEEL_ICON 0 "NO_ICON" 1 "GRAY_ICON" 2 "GRAY_ICON_FLASHING" 3 "GREEN_ICON" 4 "GREEN_ICON_FLASHING" 5 "RED_ICON" 6 "RED_ICON_FLASHING" 7 "YELLOW_ICON";
VAL_ 689 AUDIBLE_TONE 0 "NO_TONE" 1 "CONT" 2 "FAST_BEEP_CONT" 3 "TRIPLE_FAST_BEEP_CONT" 4 "SLOW_BEEP_CONT" 5 "QUAD_SLOW_BEEP_CONT" 6 "SINGLE_BEEP_ONCE" 7 "DOUBLE_BEEP_ONCE";
VAL_ 689 LARGE_STEERING_WHEEL_ICON 0 "NO_STEERINGWHEEL" 1 "GRAY_STEERINGWHEEL" 2 "GREEN_STEERINGWHEEL" 3 "GREEN_STEERINGWHEEL_FLASHING";
VAL_ 853 ODOMETER_UNITS 96 "MPH" 64 "KM";
VAL_ 976 RIGHT_BLINKER_STATUS 3 "Off" 1 "On";
VAL_ 976 LEFT_BLINKER_STATUS 3 "Off" 1 "On";
VAL_ 976 GEAR_SHIFTER 7 "B" 4 "D" 3 "N" 2 "R" 1 "P";
VAL_ 1008 WARNING_STATUS 13 "LIT_INDICATOR" 0 "UNLIT_INDICATOR" 5 "FLASH_INDICATOR";
VAL_ 1011 WARNING_STATUS 13 "LIT_INDICATOR" 0 "UNLIT_INDICATOR" 5 "FLASH_INDICATOR";
VAL_ 1057 GEAR_SHIFTER 7 "B" 4 "D" 3 "N" 2 "R" 1 "P";
VAL_ 1228 PROPILOT_NA_MSGS 0 "NO_MSG" 1 "NA_FRONT_CAMERA_IMPARED" 2 "STEERING_ASSIST_ON_STANDBY" 3 "NA_PARKING_ASSIST_ENABLED" 4 "STEER_ASSIST_CURRENTLY_NA" 5 "NA_BAD_WEATHER" 6 "NA_PARK_BRAKE_ON" 7 "NA_SEATBELT_NOT_FASTENED";
VAL_ 1228 BOTTOM_MSG 0 "OK_STEER_ASSIST_SETTINGS" 1 "NO_MSG" 2 "PRESS_SET_TO_SET_SPEED" 3 "PRESS_RES_SET_TO_CHANGE_SPEED" 4 "PRESS_RES_TO_RESTART" 5 "NO_MSG" 6 "CRUISE_NOT_AVAIL" 7 "NO_MSG";
VAL_ 1573 HEADLIGHT_STATUS 0 "LIGHTS_OFF";
